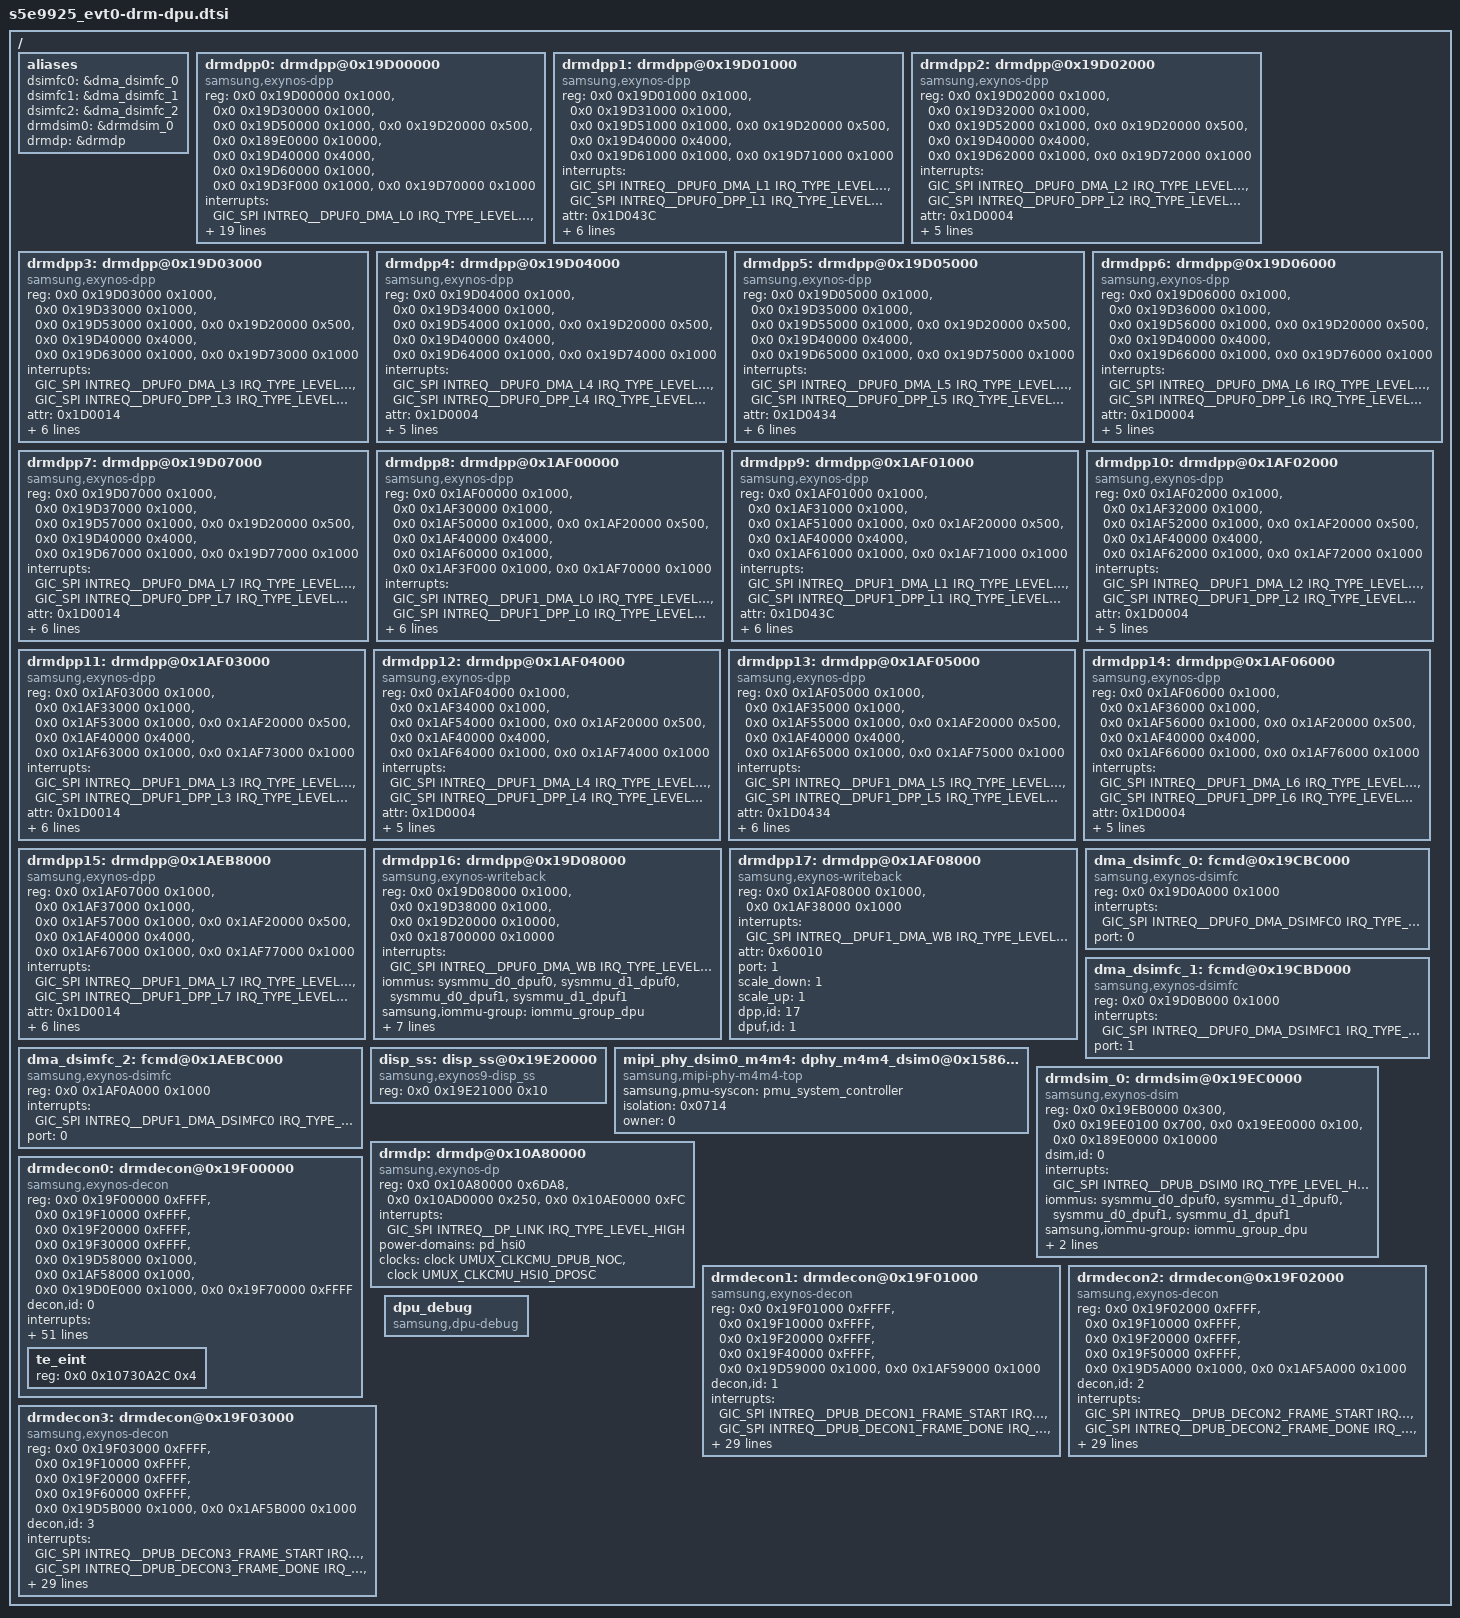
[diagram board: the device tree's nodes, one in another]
/*
 * SAMSUNG EXYNOS9925 SoC device tree source
 *
 * Copyright (c) 2021 Samsung Electronics Co., Ltd.
 *		http://www.samsung.com
 *
 * SAMSUNG EXYNOS9925 SoC device nodes are listed in this file.
 * EXYNOS based board files can include this file and provide
 * values for board specfic bindings.
 *
 * This program is free software; you can redistribute it and/or modify
 * it under the terms of the GNU General Public License version 2 as
 * published by the Free Software Foundation.
 */

#include <dt-bindings/interrupt-controller/arm-gic.h>
#include <dt-bindings/interrupt-controller/s5e9925_evt0.h>
#include <dt-bindings/clock/s5e9925_evt0.h>
#include <dt-bindings/soc/samsung/s5e9925-devfreq.h>
#include <dt-bindings/display/exynos-display.h>
#include "s5e9925_evt0-pinctrl.dtsi"
#include "s5e9925-display-timing.dtsi"

/ {
	aliases {
		dsimfc0 = &dma_dsimfc_0;
		dsimfc1 = &dma_dsimfc_1;
		dsimfc2 = &dma_dsimfc_2;
		drmdsim0 = &drmdsim_0;
		drmdp = &drmdp;
	};

	drmdpp0: drmdpp@0x19D00000 {	/* L0 */
		compatible = "samsung,exynos-dpp";
		reg = <0x0 0x19D00000 0x1000>,	/* DPU_DMA */
		      <0x0 0x19D30000 0x1000>,	/* DPP */
		      <0x0 0x19D50000 0x1000>,	/* SRAMCON */
		      <0x0 0x19D20000 0x500>,	/* vOTF_DPUF0 */
		      <0x0 0x189E0000 0x10000>,	/* vOTF_MSCL(for vOTF sysmmu) */
		      <0x0 0x19D40000 0x4000>,  /* SCL_COEF */
		      <0x0 0x19D60000 0x1000>,  /* HDR_COMM */
		      <0x0 0x19D3F000 0x1000>,  /* DPP_DEBUG */
		      <0x0 0x19D70000 0x1000>;  /* MCD HDR*/
		reg-names = "dma", "dpp", "sramc", "votf", "votf_mscl",
			    "scl_coef", "hdr_comm", "dpp_debug", "mcd_hdr";

		/* DPU_DMA IRQ, DPP IRQ */
		interrupts = <GIC_SPI INTREQ__DPUF0_DMA_L0 IRQ_TYPE_LEVEL_HIGH>,
			   <GIC_SPI INTREQ__DPUF0_DPP_L0 IRQ_TYPE_LEVEL_HIGH>;
		interrupt-names = "dma", "dpp";

		iommus = <&sysmmu_d0_dpuf0>, <&sysmmu_d1_dpuf0>,
		         <&sysmmu_d0_dpuf1>, <&sysmmu_d1_dpuf1>;
		samsung,iommu-group = <&iommu_group_dpu>;

		/* Each bit indicates DPP attribute */
		/* 0:AFBC/SAJC 1:BLOCK 2:FLIP 3:ROT 4:CSC 5:SCALE 6:HDR 7:C_HDR */
		/* 8:C_HDR10 9:WCG 10:SBWC 16:IDMA 17:ODMA 18:DPP 19:SRAMC */
		/* 20:HDR_COMM */
		attr = <0x1D0004>;
		port = <0>; /* AXI port number */

		/* 1: scale X, 2: 1/2x scale down, 4: 1/4x scale down */
		scale_down = <1>;
		/* 1: scale X, 2: 2x scale up, 4: 4x scale up */
		scale_up = <1>;

		dpp,id = <0>;
		dpuf,id = <0>;

		dpp,rsc_check;
		rsc_sajc = <1>;
		rsc_sbwc = <2>;
		rsc_rot = <1>;
		rsc_scl = <2>;
		rsc_itp_csc = <4>;
		rsc_sramc = <2>;
		rsc_sram_w = <1024>;
		rsc_sram = <42>;
	};

	drmdpp1: drmdpp@0x19D01000 {	/* L1 */
		compatible = "samsung,exynos-dpp";
		reg = <0x0 0x19D01000 0x1000>,
		      <0x0 0x19D31000 0x1000>,
		      <0x0 0x19D51000 0x1000>,
		      <0x0 0x19D20000 0x500>,
		      <0x0 0x19D40000 0x4000>,
		      <0x0 0x19D61000 0x1000>,
		      <0x0 0x19D71000 0x1000>;  /* MCD HDR*/
		reg-names = "dma", "dpp", "sramc", "votf", "scl_coef", "hdr_comm", "mcd_hdr";

		interrupts = <GIC_SPI INTREQ__DPUF0_DMA_L1 IRQ_TYPE_LEVEL_HIGH>,
			   <GIC_SPI INTREQ__DPUF0_DPP_L1 IRQ_TYPE_LEVEL_HIGH>;
		interrupt-names = "dma", "dpp";

		attr = <0x1D043C>;
		port = <0>;
		scale_down = <4>;
		scale_up = <8>;

		dpp,id = <1>;
		dpuf,id = <0>;
		dpp,video;
	};

	drmdpp2: drmdpp@0x19D02000 {	/* L2 */
		compatible = "samsung,exynos-dpp";
		reg = <0x0 0x19D02000 0x1000>,
		      <0x0 0x19D32000 0x1000>,
		      <0x0 0x19D52000 0x1000>,
		      <0x0 0x19D20000 0x500>,
		      <0x0 0x19D40000 0x4000>,
		      <0x0 0x19D62000 0x1000>,
		      <0x0 0x19D72000 0x1000>;  /* MCD HDR*/
		reg-names = "dma", "dpp", "sramc", "votf", "scl_coef", "hdr_comm", "mcd_hdr";

		interrupts = <GIC_SPI INTREQ__DPUF0_DMA_L2 IRQ_TYPE_LEVEL_HIGH>,
			   <GIC_SPI INTREQ__DPUF0_DPP_L2 IRQ_TYPE_LEVEL_HIGH>;
		interrupt-names = "dma", "dpp";

		attr = <0x1D0004>;
		port = <0>;
		scale_down = <1>;
		scale_up = <1>;

		dpp,id = <2>;
		dpuf,id = <0>;
	};

	drmdpp3: drmdpp@0x19D03000 {	/* L3 */
		compatible = "samsung,exynos-dpp";
		reg = <0x0 0x19D03000 0x1000>,
		      <0x0 0x19D33000 0x1000>,
		      <0x0 0x19D53000 0x1000>,
		      <0x0 0x19D20000 0x500>,
		      <0x0 0x19D40000 0x4000>,
		      <0x0 0x19D63000 0x1000>,
		      <0x0 0x19D73000 0x1000>;  /* MCD HDR*/
		reg-names = "dma", "dpp", "sramc", "votf", "scl_coef", "hdr_comm", "mcd_hdr";

		interrupts = <GIC_SPI INTREQ__DPUF0_DMA_L3 IRQ_TYPE_LEVEL_HIGH>,
			   <GIC_SPI INTREQ__DPUF0_DPP_L3 IRQ_TYPE_LEVEL_HIGH>;
		interrupt-names = "dma", "dpp";

		attr = <0x1D0014>;
		port = <0>;
		scale_down = <1>;
		scale_up = <1>;

		dpp,id = <3>;
		dpuf,id = <0>;
		dpp,video;
	};

	drmdpp4: drmdpp@0x19D04000 {	/* L4 */
		compatible = "samsung,exynos-dpp";
		reg = <0x0 0x19D04000 0x1000>,
		      <0x0 0x19D34000 0x1000>,
		      <0x0 0x19D54000 0x1000>,
		      <0x0 0x19D20000 0x500>,
		      <0x0 0x19D40000 0x4000>,
		      <0x0 0x19D64000 0x1000>,
		      <0x0 0x19D74000 0x1000>;  /* MCD HDR*/
		reg-names = "dma", "dpp", "sramc", "votf", "scl_coef", "hdr_comm", "mcd_hdr";

		interrupts = <GIC_SPI INTREQ__DPUF0_DMA_L4 IRQ_TYPE_LEVEL_HIGH>,
			   <GIC_SPI INTREQ__DPUF0_DPP_L4 IRQ_TYPE_LEVEL_HIGH>;
		interrupt-names = "dma", "dpp";

		attr = <0x1D0004>;
		port = <1>;
		scale_down = <1>;
		scale_up = <1>;

		dpp,id = <4>;
		dpuf,id = <0>;
	};

	drmdpp5: drmdpp@0x19D05000 {	/* L5 */
		compatible = "samsung,exynos-dpp";
		reg = <0x0 0x19D05000 0x1000>,
		      <0x0 0x19D35000 0x1000>,
		      <0x0 0x19D55000 0x1000>,
		      <0x0 0x19D20000 0x500>,
		      <0x0 0x19D40000 0x4000>,
		      <0x0 0x19D65000 0x1000>,
		      <0x0 0x19D75000 0x1000>;  /* MCD HDR*/
		reg-names = "dma", "dpp", "sramc", "votf", "scl_coef", "hdr_comm", "mcd_hdr";

		interrupts = <GIC_SPI INTREQ__DPUF0_DMA_L5 IRQ_TYPE_LEVEL_HIGH>,
			   <GIC_SPI INTREQ__DPUF0_DPP_L5 IRQ_TYPE_LEVEL_HIGH>;
		interrupt-names = "dma", "dpp";

		attr = <0x1D0434>;
		port = <1>;
		scale_down = <4>;
		scale_up = <8>;

		dpp,id = <5>;
		dpuf,id = <0>;
		dpp,video;
	};

	drmdpp6: drmdpp@0x19D06000 {	/* L6 */
		compatible = "samsung,exynos-dpp";
		reg = <0x0 0x19D06000 0x1000>,
		      <0x0 0x19D36000 0x1000>,
		      <0x0 0x19D56000 0x1000>,
		      <0x0 0x19D20000 0x500>,
		      <0x0 0x19D40000 0x4000>,
		      <0x0 0x19D66000 0x1000>,
		      <0x0 0x19D76000 0x1000>;  /* MCD HDR*/
		reg-names = "dma", "dpp", "sramc", "votf", "scl_coef", "hdr_comm", "mcd_hdr";

		interrupts = <GIC_SPI INTREQ__DPUF0_DMA_L6 IRQ_TYPE_LEVEL_HIGH>,
			   <GIC_SPI INTREQ__DPUF0_DPP_L6 IRQ_TYPE_LEVEL_HIGH>;
		interrupt-names = "dma", "dpp";

		attr = <0x1D0004>;
		port = <1>;
		scale_down = <1>;
		scale_up = <1>;

		dpp,id = <6>;
		dpuf,id = <0>;
	};

	drmdpp7: drmdpp@0x19D07000 {	/* L7 */
		compatible = "samsung,exynos-dpp";
		reg = <0x0 0x19D07000 0x1000>,
		      <0x0 0x19D37000 0x1000>,
		      <0x0 0x19D57000 0x1000>,
		      <0x0 0x19D20000 0x500>,
		      <0x0 0x19D40000 0x4000>,
		      <0x0 0x19D67000 0x1000>,
		      <0x0 0x19D77000 0x1000>;  /* MCD HDR*/
		reg-names = "dma", "dpp", "sramc", "votf", "scl_coef", "hdr_comm", "mcd_hdr";

		interrupts = <GIC_SPI INTREQ__DPUF0_DMA_L7 IRQ_TYPE_LEVEL_HIGH>,
			   <GIC_SPI INTREQ__DPUF0_DPP_L7 IRQ_TYPE_LEVEL_HIGH>;
		interrupt-names = "dma", "dpp";

		attr = <0x1D0014>;
		port = <1>;
		scale_down = <1>;
		scale_up = <1>;

		dpp,id = <7>;
		dpuf,id = <0>;
		dpp,video;
	};

	drmdpp8: drmdpp@0x1AF00000 {	/* L8 */
		compatible = "samsung,exynos-dpp";
		reg = <0x0 0x1AF00000 0x1000>,
		      <0x0 0x1AF30000 0x1000>,
		      <0x0 0x1AF50000 0x1000>,
		      <0x0 0x1AF20000 0x500>,
		      <0x0 0x1AF40000 0x4000>,
		      <0x0 0x1AF60000 0x1000>,
		      <0x0 0x1AF3F000 0x1000>,
		      <0x0 0x1AF70000 0x1000>;  /* MCD HDR*/
		reg-names = "dma", "dpp", "sramc", "votf", "scl_coef",
			"hdr_comm", "dpp_debug", "mcd_hdr";

		interrupts = <GIC_SPI INTREQ__DPUF1_DMA_L0 IRQ_TYPE_LEVEL_HIGH>,
			   <GIC_SPI INTREQ__DPUF1_DPP_L0 IRQ_TYPE_LEVEL_HIGH>;
		interrupt-names = "dma", "dpp";

		attr = <0x1D0004>;
		port = <0>;
		scale_down = <1>;
		scale_up = <1>;

		dpp,id = <8>;
		dpuf,id = <1>;
	};

	drmdpp9: drmdpp@0x1AF01000 {	/* L9 */
		compatible = "samsung,exynos-dpp";
		reg = <0x0 0x1AF01000 0x1000>,
		      <0x0 0x1AF31000 0x1000>,
		      <0x0 0x1AF51000 0x1000>,
		      <0x0 0x1AF20000 0x500>,
		      <0x0 0x1AF40000 0x4000>,
		      <0x0 0x1AF61000 0x1000>,
		      <0x0 0x1AF71000 0x1000>;  /* MCD HDR*/
		reg-names = "dma", "dpp", "sramc", "votf", "scl_coef", "hdr_comm", "mcd_hdr";

		interrupts = <GIC_SPI INTREQ__DPUF1_DMA_L1 IRQ_TYPE_LEVEL_HIGH>,
			   <GIC_SPI INTREQ__DPUF1_DPP_L1 IRQ_TYPE_LEVEL_HIGH>;
		interrupt-names = "dma", "dpp";

		attr = <0x1D043C>;
		port = <0>;
		scale_down = <4>;
		scale_up = <8>;

		dpp,id = <9>;
		dpuf,id = <1>;
		dpp,video;
	};

	drmdpp10: drmdpp@0x1AF02000 {	/* L10 */
		compatible = "samsung,exynos-dpp";
		reg = <0x0 0x1AF02000 0x1000>,
		      <0x0 0x1AF32000 0x1000>,
		      <0x0 0x1AF52000 0x1000>,
		      <0x0 0x1AF20000 0x500>,
		      <0x0 0x1AF40000 0x4000>,
		      <0x0 0x1AF62000 0x1000>,
		      <0x0 0x1AF72000 0x1000>;  /* MCD HDR*/
		reg-names = "dma", "dpp", "sramc", "votf", "scl_coef", "hdr_comm", "mcd_hdr";

		interrupts = <GIC_SPI INTREQ__DPUF1_DMA_L2 IRQ_TYPE_LEVEL_HIGH>,
			   <GIC_SPI INTREQ__DPUF1_DPP_L2 IRQ_TYPE_LEVEL_HIGH>;
		interrupt-names = "dma", "dpp";

		attr = <0x1D0004>;
		port = <0>;
		scale_down = <1>;
		scale_up = <1>;

		dpp,id = <10>;
		dpuf,id = <1>;
	};

	drmdpp11: drmdpp@0x1AF03000 {	/* L11 */
		compatible = "samsung,exynos-dpp";
		reg = <0x0 0x1AF03000 0x1000>,
		      <0x0 0x1AF33000 0x1000>,
		      <0x0 0x1AF53000 0x1000>,
		      <0x0 0x1AF20000 0x500>,
		      <0x0 0x1AF40000 0x4000>,
		      <0x0 0x1AF63000 0x1000>,
		      <0x0 0x1AF73000 0x1000>;  /* MCD HDR*/
		reg-names = "dma", "dpp", "sramc", "votf", "scl_coef", "hdr_comm", "mcd_hdr";

		interrupts = <GIC_SPI INTREQ__DPUF1_DMA_L3 IRQ_TYPE_LEVEL_HIGH>,
			   <GIC_SPI INTREQ__DPUF1_DPP_L3 IRQ_TYPE_LEVEL_HIGH>;
		interrupt-names = "dma", "dpp";

		attr = <0x1D0014>;
		port = <0>;
		scale_down = <1>;
		scale_up = <1>;

		dpp,id = <11>;
		dpuf,id = <1>;
		dpp,video;
	};

	drmdpp12: drmdpp@0x1AF04000 {	/* L12 */
		compatible = "samsung,exynos-dpp";
		reg = <0x0 0x1AF04000 0x1000>,
		      <0x0 0x1AF34000 0x1000>,
		      <0x0 0x1AF54000 0x1000>,
		      <0x0 0x1AF20000 0x500>,
		      <0x0 0x1AF40000 0x4000>,
		      <0x0 0x1AF64000 0x1000>,
		      <0x0 0x1AF74000 0x1000>;  /* MCD HDR*/
		reg-names = "dma", "dpp", "sramc", "votf", "scl_coef", "hdr_comm", "mcd_hdr";

		interrupts = <GIC_SPI INTREQ__DPUF1_DMA_L4 IRQ_TYPE_LEVEL_HIGH>,
			   <GIC_SPI INTREQ__DPUF1_DPP_L4 IRQ_TYPE_LEVEL_HIGH>;
		interrupt-names = "dma", "dpp";

		attr = <0x1D0004>;
		port = <1>;
		scale_down = <1>;
		scale_up = <1>;

		dpp,id = <12>;
		dpuf,id = <1>;
	};

	drmdpp13: drmdpp@0x1AF05000 {	/* L13 */
		compatible = "samsung,exynos-dpp";
		reg = <0x0 0x1AF05000 0x1000>,
		      <0x0 0x1AF35000 0x1000>,
		      <0x0 0x1AF55000 0x1000>,
		      <0x0 0x1AF20000 0x500>,
		      <0x0 0x1AF40000 0x4000>,
		      <0x0 0x1AF65000 0x1000>,
		      <0x0 0x1AF75000 0x1000>;  /* MCD HDR*/
		reg-names = "dma", "dpp", "sramc", "votf", "scl_coef", "hdr_comm", "mcd_hdr";

		interrupts = <GIC_SPI INTREQ__DPUF1_DMA_L5 IRQ_TYPE_LEVEL_HIGH>,
			   <GIC_SPI INTREQ__DPUF1_DPP_L5 IRQ_TYPE_LEVEL_HIGH>;
		interrupt-names = "dma", "dpp";

		attr = <0x1D0434>;
		port = <1>;
		scale_down = <4>;
		scale_up = <8>;

		dpp,id = <13>;
		dpuf,id = <1>;
		dpp,video;
	};

	drmdpp14: drmdpp@0x1AF06000 {	/* L14 */
		compatible = "samsung,exynos-dpp";
		reg = <0x0 0x1AF06000 0x1000>,
		      <0x0 0x1AF36000 0x1000>,
		      <0x0 0x1AF56000 0x1000>,
		      <0x0 0x1AF20000 0x500>,
		      <0x0 0x1AF40000 0x4000>,
		      <0x0 0x1AF66000 0x1000>,
		      <0x0 0x1AF76000 0x1000>;  /* MCD HDR*/
		reg-names = "dma", "dpp", "sramc", "votf", "scl_coef", "hdr_comm", "mcd_hdr";

		interrupts = <GIC_SPI INTREQ__DPUF1_DMA_L6 IRQ_TYPE_LEVEL_HIGH>,
			   <GIC_SPI INTREQ__DPUF1_DPP_L6 IRQ_TYPE_LEVEL_HIGH>;
		interrupt-names = "dma", "dpp";

		/* DPP[18]/IDMA[16]/CSC[4]/FLIP[2]/BLOCK[1]/AFBC[0] */
		attr = <0x1D0004>;
		port = <1>;
		scale_down = <1>;
		scale_up = <1>;

		dpp,id = <14>;
		dpuf,id = <1>;
	};

	drmdpp15: drmdpp@0x1AEB8000 {	/* L15 */
		compatible = "samsung,exynos-dpp";
		reg = <0x0 0x1AF07000 0x1000>,
		      <0x0 0x1AF37000 0x1000>,
		      <0x0 0x1AF57000 0x1000>,
		      <0x0 0x1AF20000 0x500>,
		      <0x0 0x1AF40000 0x4000>,
		      <0x0 0x1AF67000 0x1000>,
		      <0x0 0x1AF77000 0x1000>;  /* MCD HDR*/
		reg-names = "dma", "dpp", "sramc", "votf", "scl_coef", "hdr_comm", "mcd_hdr";

		interrupts = <GIC_SPI INTREQ__DPUF1_DMA_L7 IRQ_TYPE_LEVEL_HIGH>,
			   <GIC_SPI INTREQ__DPUF1_DPP_L7 IRQ_TYPE_LEVEL_HIGH>;
		interrupt-names = "dma", "dpp";

		attr = <0x1D0014>;
		port = <1>;
		scale_down = <1>;
		scale_up = <1>;

		dpp,id = <15>;
		dpuf,id = <1>;
		dpp,video;
	};

	drmdpp16: drmdpp@0x19D08000 {
		compatible = "samsung,exynos-writeback";
		reg = <0x0 0x19D08000 0x1000>,
			  <0x0 0x19D38000 0x1000>,
			  <0x0 0x19D20000 0x10000>,
			  <0x0 0x18700000 0x10000>;
		reg-names = "dma", "dpp", "votf", "votf_mfc";

		interrupts = <GIC_SPI INTREQ__DPUF0_DMA_WB IRQ_TYPE_LEVEL_HIGH>;
		interrupt-names = "dma";

		iommus = <&sysmmu_d0_dpuf0>, <&sysmmu_d1_dpuf0>,
		         <&sysmmu_d0_dpuf1>, <&sysmmu_d1_dpuf1>;
		samsung,iommu-group = <&iommu_group_dpu>;

		attr = <0x60010>;
		port = <1>;
		scale_down = <1>;
		scale_up = <1>;

		votf_o,enabled;

		dpp,id = <16>;
		dpuf,id = <0>;
	};

	drmdpp17: drmdpp@0x1AF08000 {
		compatible = "samsung,exynos-writeback";
		reg = <0x0 0x1AF08000 0x1000>,
			  <0x0 0x1AF38000 0x1000>;
		reg-names = "dma", "dpp";

		interrupts = <GIC_SPI INTREQ__DPUF1_DMA_WB IRQ_TYPE_LEVEL_HIGH>;
		interrupt-names = "dma";

		attr = <0x60010>;
		port = <1>;
		scale_down = <1>;
		scale_up = <1>;

		dpp,id = <17>;
		dpuf,id = <1>;
	};

	dma_dsimfc_0: fcmd@0x19CBC000 {	/* DPUF0_DSIMFC_L0 */
		compatible = "samsung,exynos-dsimfc";
		/* DPU_DMA */
		reg = <0x0 0x19D0A000 0x1000>;
		/* DPU_DMA IRQ */
		interrupts = <GIC_SPI INTREQ__DPUF0_DMA_DSIMFC0 IRQ_TYPE_LEVEL_HIGH>;
		port = <0>; /* AXI port number */
	};

	dma_dsimfc_1: fcmd@0x19CBD000 {	/* DPUF0_DSIMFC_L1 */
		compatible = "samsung,exynos-dsimfc";
		/* DPU_DMA */
		reg = <0x0 0x19D0B000 0x1000>;
		/* DPU_DMA IRQ */
		interrupts = <GIC_SPI INTREQ__DPUF0_DMA_DSIMFC1 IRQ_TYPE_LEVEL_HIGH>;
		port = <1>; /* AXI port number */
	};

	dma_dsimfc_2: fcmd@0x1AEBC000 {	/* DPUF1_DSIMFC_L2 */
		compatible = "samsung,exynos-dsimfc";
		/* DPU_DMA */
		reg = <0x0 0x1AF0A000 0x1000>;
		/* DPU_DMA IRQ */
		interrupts = <GIC_SPI INTREQ__DPUF1_DMA_DSIMFC0 IRQ_TYPE_LEVEL_HIGH>;
		port = <0>; /* AXI port number */
	};

	disp_ss: disp_ss@0x19E20000 {
		compatible = "samsung,exynos9-disp_ss";
		reg = <0x0 0x19E21000 0x10>;
		reg-names = "sys";
	};

	mipi_phy_dsim0_m4m4: dphy_m4m4_dsim0@0x15860000 {
		compatible = "samsung,mipi-phy-m4m4-top";
		samsung,pmu-syscon = <&pmu_system_controller>;
		isolation = <0x0714>;
		owner = <0>; /* 0: DSI_0 1: DSI_1 */
		#phy-cells = <1>;
	};

	drmdsim_0: drmdsim@0x19EC0000 {
		compatible = "samsung,exynos-dsim";
		reg = <0x0 0x19EB0000 0x300>,	/* DSIM0 */
		      <0x0 0x19EE0100 0x700>,	/* DCPHY_M4M4_TOP */
		      <0x0 0x19EE0000 0x100>,	/* DCPHY_M4M4_COMMON */
		      <0x0 0x189E0000 0x10000>;	/* vOTF_MSCL(for vOTF sysmmu) */
		reg-names = "dsi", "dphy", "dphy-extra", "votf";

		dsim,id = <0>;

		interrupts = <GIC_SPI INTREQ__DPUB_DSIM0 IRQ_TYPE_LEVEL_HIGH>;
		interrupt-names = "dsim";

		iommus = <&sysmmu_d0_dpuf0>, <&sysmmu_d1_dpuf0>,
		         <&sysmmu_d0_dpuf1>, <&sysmmu_d1_dpuf1>;
		samsung,iommu-group = <&iommu_group_dpu>;

		phys = <&mipi_phy_dsim0_m4m4 0>;
		phy-names = "dsim_dphy";

		dsim_mode = <&dsim_modes>;

		#address-cells = <1>;
		#size-cells = <0>;

	};

	drmdp: drmdp@0x10A80000 {
		compatible = "samsung,exynos-dp";
		/* IP resources(address, irq, sysmmu, power, secure, clock) */
		reg = <0x0 0x10A80000 0x6DA8>,
			<0x0 0x10AD0000 0x250>,
			<0x0 0x10AE0000 0xFC>;
		reg-names = "dp_link", "usbdpphy_ctrl", "usbdpphy_tca_ctrl";

		interrupts = <GIC_SPI INTREQ__DP_LINK IRQ_TYPE_LEVEL_HIGH>;
		interrupt-names = "dp";

		power-domains = <&pd_hsi0>;
		/* clock */
		clock-names = "aclk", "dposc_clk";
		clocks = <&clock UMUX_CLKCMU_DPUB_NOC>, <&clock UMUX_CLKCMU_HSI0_DPOSC>;
	};

	drmdecon0: drmdecon@0x19F00000 {
		compatible = "samsung,exynos-decon";
		reg = <0x0 0x19F00000 0xFFFF>,	/* DECON0_MAIN */
		      <0x0 0x19F10000 0xFFFF>,	/* DECON_WIN */
		      <0x0 0x19F20000 0xFFFF>,	/* DECON_SUB */
		      <0x0 0x19F30000 0xFFFF>,	/* DECON0_WINCON */
		      <0x0 0x19D58000 0x1000>,	/* SRAMC0_D0 - DPUF0 */
		      <0x0 0x1AF58000 0x1000>,	/* SRAMC1_D0 - DPUF1 */
		      <0x0 0x19D0E000 0x1000>,  /* DQE EDMA*/
		      <0x0 0x19F70000 0xFFFF>;	/* DQE */
		reg-names = "main", "win", "sub", "wincon", "sramc_d",
			    "sramc1_d", "edma", "dqe";

		decon,id = <0>;

		interrupts = <GIC_SPI INTREQ__DPUB_DECON0_FRAME_START
				IRQ_TYPE_LEVEL_HIGH>,
			     <GIC_SPI INTREQ__DPUB_DECON0_FRAME_DONE
				IRQ_TYPE_LEVEL_HIGH>,
			     <GIC_SPI INTREQ__DPUB_DECON0_EXTRA
				IRQ_TYPE_LEVEL_HIGH>,
			     <GIC_SPI INTREQ__DPUF0_DMA_CGC
				IRQ_TYPE_LEVEL_HIGH>,
				<GIC_SPI INTREQ__DPUF0_SRAMCON_D0
				IRQ_TYPE_LEVEL_HIGH>,
				<GIC_SPI INTREQ__DPUF1_SRAMCON_D0
				IRQ_TYPE_LEVEL_HIGH>;
		interrupt-names = "frame_start", "frame_done", "extra",
				  "edma", "sramc_d", "sramc1_d";

		iommus = <&sysmmu_d0_dpuf0>, <&sysmmu_d1_dpuf0>,
		         <&sysmmu_d0_dpuf1>, <&sysmmu_d1_dpuf1>;
		samsung,iommu-group = <&iommu_group_dpu>;
		/* To use secure buffer address range. If you not set this, */
		/* normal buffer is transfered on DRM scenario */
		samsung,tzmp;

		/* clock */
		clock-names = "aclk";
		clocks = <&clock UMUX_CLKCMU_DPUB_NOC>;

		/* pinctrl */
		pinctrl-names = "hw_te_on", "hw_te_off";
		pinctrl-0 = <&decon_0_te_on>;
		pinctrl-1 = <&decon_0_te_off>;

		max_win = <16>;
		/* 0: video mode, 1: MIPI command mode 2: DP command mode */
		op_mode = <1>;
		trig_mode = <0>;   /* 0: hw trigger, 1: sw trigger */
		out_type = <0x1>; /* BIT0:DSI0, BIT1:DSI1, BIT4:DP0, BIT5:DP1 */

		/* 0: from DDI0, 1: from DDI1, 2: from DDI2 3: not receive TE */
		te_from = <0>;

		/* BTS */
		ppc = <2>;			/* pixel per clock */
		ppc_rotator = <8>;		/* rotator ppc */
		ppc_scaler = <4>;		/* scaler ppc */
		delay_comp = <4>;		/* line delay for sajc or sbwc : DMA */
		delay_scaler = <3>;		/* line delay for scaler : DPP */
		inner_width = <16>;		/* internal processing width : worst 16-Byte*/

		/* bus info */
		bus_width = <32>;		/* 32-Byte : 256-bit bus */
		rot_util = <60>;		/* MIF_UTIL(65%) - 5%: UTIL gets worse at rotation */

		/* dpu dvfs */
		dfs_lv_cnt = <9>;
		dfs_lv = <800000 663000 533000 468000 400000 332000 200000 133000 50000>;

		/* Urgent */
		rd_en = <0>; /* defaultly disable */
		rd_hi_thres = <0x800>;
		rd_lo_thres = <0x400>;
		rd_wait_cycle = <0x10>;
		wr_en = <0>; /* defaultly disable */
		wr_hi_thres = <0x0>;
		wr_lo_thres = <0x0>;

		/* DTA */
		dta_en = <0>; /* defaultly disable */
		dta_hi_thres = <0x3200>;
		dta_lo_thres = <0x600>;

		/* DQE */
		dqe_preset_cnt = <2>;
		/*
		* <colormode(2Byte)|renderIntent(2Byte) x 4> for 1 preset
		* 0xFFFFFFFF: not set, 0xFFFF for CM or RI: select all
		* ex) 0xFFFF0006: all CM / 6 RI, 0x0001FFFF: 1 CM / all RI
		*/
		dqe_preset = 	<0xFFFF0002 0xFFFF0003 0xFFFFFFFF 0xFFFFFFFF>,
									<0xFFFFFFFF 0xFFFFFFFF 0xFFFFFFFF 0xFFFFFFFF>;

		/* EINT for TE */
		gpios = <&gpg2 0 0xf>;

		dpps = <&drmdpp0 &drmdpp1 &drmdpp2 &drmdpp3 &drmdpp4 &drmdpp5
			&drmdpp6 &drmdpp7 &drmdpp8 &drmdpp9 &drmdpp10
			&drmdpp11 &drmdpp12 &drmdpp13 &drmdpp14	&drmdpp15>;

		/*
		 * connector type that can be connected to the DECON. please
		 * refer to enum exynos_drm_output_type in exynos_drm_drv.h
		 *
		 * DSI0(0x1), DSI1(0x2), VIDI(0x8)
		 */
		connector = <0x1 0x2 0x8>;

		hibernation;
		partial-update;

		#address-cells = <2>;
		#size-cells = <1>;
		ranges;

		/* sw te pending register */
		te_eint {
			/* NWEINT_GPG2_PEND */
			reg = <0x0 0x10730A2C 0x4>;
		};
	};

	drmdecon1: drmdecon@0x19F01000 {
		compatible = "samsung,exynos-decon";
		reg = <0x0 0x19F01000 0xFFFF>,	/* DECON0_MAIN */
		      <0x0 0x19F10000 0xFFFF>,	/* DECON_WIN */
		      <0x0 0x19F20000 0xFFFF>,	/* DECON_SUB */
		      <0x0 0x19F40000 0xFFFF>,	/* DECON0_WINCON */
		      <0x0 0x19D59000 0x1000>,	/* SRAMC0_D1 - DPUF0 */
		      <0x0 0x1AF59000 0x1000>;	/* SRAMC1_D1 - DPUF1 */
		reg-names = "main", "win", "sub", "wincon", "sramc_d", "sramc1_d";

		decon,id = <1>;

		interrupts = <GIC_SPI INTREQ__DPUB_DECON1_FRAME_START
				IRQ_TYPE_LEVEL_HIGH>,
			     <GIC_SPI INTREQ__DPUB_DECON1_FRAME_DONE
				IRQ_TYPE_LEVEL_HIGH>,
			     <GIC_SPI INTREQ__DPUB_DECON1_EXTRA
				IRQ_TYPE_LEVEL_HIGH>,
			     <GIC_SPI INTREQ__DPUF0_SRAMCON_D1
				IRQ_TYPE_LEVEL_HIGH>,
			     <GIC_SPI INTREQ__DPUF1_SRAMCON_D1
				IRQ_TYPE_LEVEL_HIGH>;
		interrupt-names = "frame_start", "frame_done", "extra",
				  "sramc_d", "sramc1_d";

		iommus = <&sysmmu_d0_dpuf0>, <&sysmmu_d1_dpuf0>,
		         <&sysmmu_d0_dpuf1>, <&sysmmu_d1_dpuf1>;
		samsung,iommu-group = <&iommu_group_dpu>;
		samsung,tzmp;

		/* clock */
		clock-names = "aclk";
		clocks = <&clock UMUX_CLKCMU_DPUB_NOC>;

		max_win = <16>;
		op_mode = <1>;
		trig_mode = <1>;	/* 0: hw trigger, 1: sw trigger */
		out_type = <0x100>;	/* BIT8: WB */

		te_from = <0>;

		/* BTS */ /* TODO: check olympus */
		ppc = <2>;		/* pixel per clock */
		ppc_rotator = <8>;		/* rotator ppc */
		ppc_scaler = <4>;		/* scaler ppc */
		delay_comp = <4>;		/* line delay for sajc or sbwc : DMA */
		delay_scaler = <3>;		/* line delay for scaler : DPP */
		inner_width = <16>;		/* internal processing width : worst 16-Byte*/

		/* bus info */
		bus_width = <32>;		/* 32-Byte : 256-bit bus */
		rot_util = <60>;		/* MIF_UTIL(65%) - 5%: UTIL gets worse at rotation */

		/* dpu dvfs */
		dfs_lv_cnt = <9>;
		dfs_lv = <800000 663000 533000 468000 400000 332000 200000 133000 50000>;

		dpps = <&drmdpp0 &drmdpp1 &drmdpp2 &drmdpp3 &drmdpp4 &drmdpp5
			&drmdpp6 &drmdpp7 &drmdpp8 &drmdpp9 &drmdpp10
			&drmdpp11 &drmdpp12 &drmdpp13 &drmdpp14	&drmdpp15>;
		connector = <0x8>;
	};

	drmdecon2: drmdecon@0x19F02000 {
		compatible = "samsung,exynos-decon";
		reg = <0x0 0x19F02000 0xFFFF>,
		      <0x0 0x19F10000 0xFFFF>,
		      <0x0 0x19F20000 0xFFFF>,
		      <0x0 0x19F50000 0xFFFF>,
		      <0x0 0x19D5A000 0x1000>,	/* SRAMC0_D2 - DPUF0 */
		      <0x0 0x1AF5A000 0x1000>;	/* SRAMC1_D2 - DPUF1 */
		reg-names = "main", "win", "sub", "wincon", "sramc_d", "sramc1_d";

		decon,id = <2>;

		interrupts = <GIC_SPI INTREQ__DPUB_DECON2_FRAME_START
				IRQ_TYPE_LEVEL_HIGH>,
			     <GIC_SPI INTREQ__DPUB_DECON2_FRAME_DONE
				IRQ_TYPE_LEVEL_HIGH>,
			     <GIC_SPI INTREQ__DPUB_DECON2_EXTRA
				IRQ_TYPE_LEVEL_HIGH>,
			     <GIC_SPI INTREQ__DPUF0_SRAMCON_D2
				IRQ_TYPE_LEVEL_HIGH>,
			     <GIC_SPI INTREQ__DPUF1_SRAMCON_D2
				IRQ_TYPE_LEVEL_HIGH>;
		interrupt-names = "frame_start", "frame_done", "extra",
				  "sramc_d", "sramc1_d";

		iommus = <&sysmmu_d0_dpuf0>, <&sysmmu_d1_dpuf0>,
		         <&sysmmu_d0_dpuf1>, <&sysmmu_d1_dpuf1>;
		samsung,iommu-group = <&iommu_group_dpu>;
		samsung,tzmp;

		/* clock */
		clock-names = "aclk";
		clocks = <&clock UMUX_CLKCMU_DPUB_NOC>;

		max_win = <16>;
		op_mode = <0>;
		trig_mode = <0>;        /* 0: hw trigger, 1: sw trigger */
		out_type = <0x10>;/* BIT0:DSI0, BIT1:DSI1, BIT4:DP0, BIT5:DP1 */

		te_from = <0>;

		ppc = <2>;			/* pixel per clock */
		ppc_rotator = <8>;		/* rotator ppc */
		ppc_scaler = <4>;		/* scaler ppc */
		delay_comp = <4>;		/* line delay for sajc or sbwc : DMA */
		delay_scaler = <3>;		/* line delay for scaler : DPP */
		inner_width = <16>;		/* internal processing width : worst 16-Byte*/

		/* bus info */
		bus_width = <32>;		/* 32-Byte : 256-bit bus */
		rot_util = <60>;		/* MIF_UTIL(65%) - 5%: UTIL gets worse at rotation */

		/* dpu dvfs */
		dfs_lv_cnt = <9>;
		dfs_lv = <800000 663000 533000 468000 400000 332000 200000 133000 50000>;

		dpps = <&drmdpp0 &drmdpp1 &drmdpp2 &drmdpp3 &drmdpp4 &drmdpp5
			&drmdpp6 &drmdpp7 &drmdpp8 &drmdpp9 &drmdpp10
			&drmdpp11 &drmdpp12 &drmdpp13 &drmdpp14	&drmdpp15>;
		/* TODO: FIX for DP */
		connector = <0x10>;
	};

	drmdecon3: drmdecon@0x19F03000 {
		compatible = "samsung,exynos-decon";
		reg = <0x0 0x19F03000 0xFFFF>,
		      <0x0 0x19F10000 0xFFFF>,
		      <0x0 0x19F20000 0xFFFF>,
		      <0x0 0x19F60000 0xFFFF>,
		      <0x0 0x19D5B000 0x1000>,	/* DPUF0_SRAMC_D3 */
		      <0x0 0x1AF5B000 0x1000>;	/* DPUF1_SRAMC_D3 */
		reg-names = "main", "win", "sub", "wincon", "sramc_d", "sramc1_d";

		decon,id = <3>;

		/* interrupt num : FRAME_START, FRMAE_DONE, EXTRA */
		interrupts = <GIC_SPI INTREQ__DPUB_DECON3_FRAME_START
				IRQ_TYPE_LEVEL_HIGH>,
			     <GIC_SPI INTREQ__DPUB_DECON3_FRAME_DONE
				IRQ_TYPE_LEVEL_HIGH>,
			     <GIC_SPI INTREQ__DPUB_DECON3_EXTRA
				IRQ_TYPE_LEVEL_HIGH>,
			     <GIC_SPI INTREQ__DPUF0_SRAMCON_D3
				IRQ_TYPE_LEVEL_HIGH>,
			     <GIC_SPI INTREQ__DPUF1_SRAMCON_D3
				IRQ_TYPE_LEVEL_HIGH>;
		interrupt-names = "frame_start", "frame_done", "extra",
				  "sramc_d", "sramc1_d";

		iommus = <&sysmmu_d0_dpuf0>, <&sysmmu_d1_dpuf0>,
		         <&sysmmu_d0_dpuf1>, <&sysmmu_d1_dpuf1>;
		samsung,iommu-group = <&iommu_group_dpu>;
		samsung,tzmp;

		/* clock */
		clock-names = "aclk";
		clocks = <&clock UMUX_CLKCMU_DPUB_NOC>;

		max_win = <16>;
		op_mode = <0>;
		trig_mode = <0>;        /* 0: hw trigger, 1: sw trigger */
		out_type = <0x10>;/* BIT0:DSI0, BIT1:DSI1, BIT4:DP0, BIT5:DP1 */

		te_from = <0>;

		ppc = <2>;			/* pixel per clock */
		ppc_rotator = <8>;		/* rotator ppc */
		ppc_scaler = <4>;		/* scaler ppc */
		delay_comp = <4>;		/* line delay for sajc or sbwc : DMA */
		delay_scaler = <3>;		/* line delay for scaler : DPP */
		inner_width = <16>;		/* internal processing width : worst 16-Byte*/

		/* bus info */
		bus_width = <32>;		/* 32-Byte : 256-bit bus */
		rot_util = <60>;		/* MIF_UTIL(65%) - 5%: UTIL gets worse at rotation */

		/* dpu dvfs */
		dfs_lv_cnt = <9>;
		dfs_lv = <800000 663000 533000 468000 400000 332000 200000 133000 50000>;

		dpps = <&drmdpp0 &drmdpp1 &drmdpp2 &drmdpp3 &drmdpp4 &drmdpp5
			&drmdpp6 &drmdpp7 &drmdpp8 &drmdpp9 &drmdpp10
			&drmdpp11 &drmdpp12 &drmdpp13 &drmdpp14	&drmdpp15>;
		/* TODO: FIX for DP */
		connector = <0x100>;
	};

	dpu_debug{
		compatible = "samsung,dpu-debug";
	//	devfreq-mif = <DEVFREQ_MIF>;
	//	devfreq-int = <DEVFREQ_INT>;
	//	devfreq-disdp = <DEVFREQ_DISP>;
	};
};
